# rtc_c register map
Vendor: Texas Instruments
Peripheral module from a debugger description file (folder MSP432).
Registers are 16-bit, read-write, no defined reset value unless marked. A register's access mark holds for its fields unless they carry their own. Offsets are as the file gives them; lines under a group give offsets from that group; [hi:lo] are bit positions; {n}, {i} and the like mark numbered series; 'fields as' and 'values as' point back to an identical list; <NAME> marks a mode.

## RTC_C
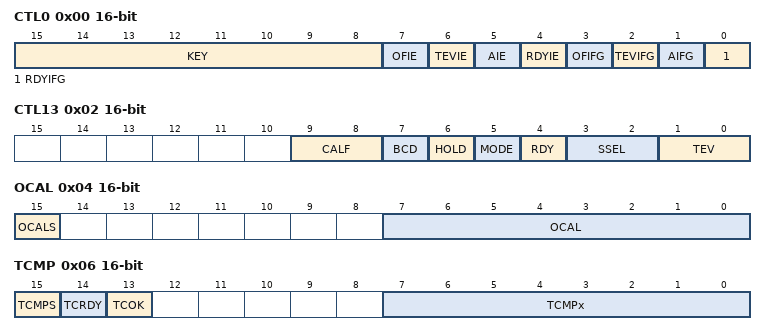
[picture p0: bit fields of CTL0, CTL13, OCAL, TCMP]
0x00 CTL0 — RTCCTL0 Register
  [15:8] KEY — Real-time clock key
  [7] OFIE — 32-kHz crystal oscillator fault interrupt enable
  [6] TEVIE — Real-time clock time event interrupt enable
  [5] AIE — Real-time clock alarm interrupt enable
  [4] RDYIE — Real-time clock ready interrupt enable
  [3] OFIFG — 32-kHz crystal oscillator fault interrupt flag
  [2] TEVIFG — Real-time clock time event interrupt flag
  [1] AIFG — Real-time clock alarm interrupt flag
  [0] RDYIFG — Real-time clock ready interrupt flag
0x02 CTL13 — RTCCTL13 Register
  [9:8] CALF — Real-time clock calibration frequency
    0=CALF__0 (No frequency output to RTCCLK pin); 1=CALF__1 (512 Hz); 2=CALF__2 (256 Hz); 3=CALF__3 (1 Hz)
  [7] BCD — Real-time clock BCD select
    0=BCD__0 (Binary (hexadecimal) code selected); 1=BCD__1 (Binary coded decimal (BCD) code selected)
  [6] HOLD — Real-time clock hold
    0=HOLD__0 (Real-time clock is operational); 1=HOLD__1 (When set, the calendar is stopped as well as the prescale count)
  [5] MODE
    1=MODE__1 (Calendar mode. Always reads a value of 1.)
  [4] RDY — Real-time clock ready
    0=RDY__0 (RTC time values in transition); 1=RDY__1 (RTC time values safe for reading)
  [3:2] SSEL — Real-time clock source select.
    0=SSEL__0 (BCLK)
  [1:0] TEV — Real-time clock time event
    0=TEV__0 (Minute changed); 1=TEV__1 (Hour changed); 2=TEV__2 (Every day at midnight (00:00)); 3=TEV__3 (Every day at noon (12:00))
0x04 OCAL — RTCOCAL Register
  [15] OCALS — Real-time clock offset error calibration sign
    0=OCALS__0 (Down calibration. Frequency adjusted down.); 1=OCALS__1 (Up calibration. Frequency adjusted up.)
  [7:0] OCAL — Real-time clock offset error calibration
0x06 TCMP — RTCTCMP Register
  [15] TCMPS — Real-time clock temperature compensation sign
    0=TCMPS__0 (Down calibration. Frequency adjusted down); 1=TCMPS__1 (Up calibration. Frequency adjusted up)
  [14] TCRDY — Real-time clock temperature compensation ready
  [13] TCOK — Real-time clock temperature compensation write OK
    0=TCOK__0 (Write to RTCTCMPx is unsuccessful); 1=TCOK__1 (Write to RTCTCMPx is successful)
  [7:0] TCMPx — Real-time clock temperature compensation
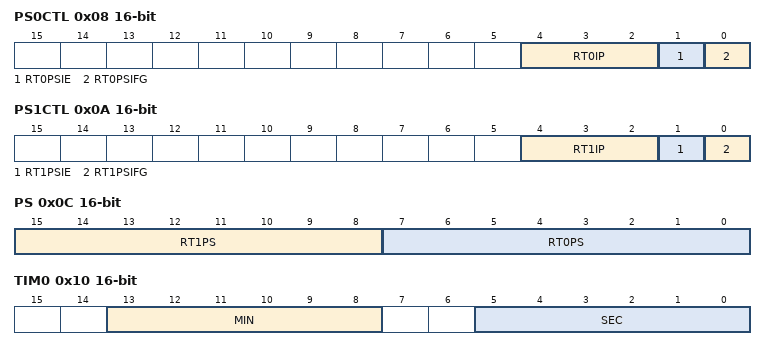
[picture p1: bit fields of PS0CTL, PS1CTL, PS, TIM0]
0x08 PS0CTL — Real-Time Clock Prescale Timer 0 Control Register
  [4:2] RT0IP — Prescale timer 0 interrupt interval
    0=RT0IP__0 (Divide by 2); 1=RT0IP__1 (Divide by 4); 2=RT0IP__2 (Divide by 8); 3=RT0IP__3 (Divide by 16); 4=RT0IP__4 (Divide by 32); 5=RT0IP__5 (Divide by 64); 6=RT0IP__6 (Divide by 128); 7=RT0IP__7 (Divide by 256)
  [1] RT0PSIE — Prescale timer 0 interrupt enable
    0=RT0PSIE__0 (Interrupt not enabled); 1=RT0PSIE__1 (Interrupt enabled)
  [0] RT0PSIFG — Prescale timer 0 interrupt flag
    0=RT0PSIFG__0 (No time event occurred); 1=RT0PSIFG__1 (Time event occurred)
0x0A PS1CTL — Real-Time Clock Prescale Timer 1 Control Register
  [4:2] RT1IP — Prescale timer 1 interrupt interval
    0=RT1IP__0 (Divide by 2); 1=RT1IP__1 (Divide by 4); 2=RT1IP__2 (Divide by 8); 3=RT1IP__3 (Divide by 16); 4=RT1IP__4 (Divide by 32); 5=RT1IP__5 (Divide by 64); 6=RT1IP__6 (Divide by 128); 7=RT1IP__7 (Divide by 256)
  [1] RT1PSIE — Prescale timer 1 interrupt enable
    0=RT1PSIE__0 (Interrupt not enabled); 1=RT1PSIE__1 (Interrupt enabled (LPM3/LPM3.5 wake-up enabled))
  [0] RT1PSIFG — Prescale timer 1 interrupt flag
    0=RT1PSIFG__0 (No time event occurred); 1=RT1PSIFG__1 (Time event occurred)
0x0C PS — Real-Time Clock Prescale Timer Counter Register
  [15:8] RT1PS — Prescale timer 1 counter value
  [7:0] RT0PS — Prescale timer 0 counter value
0x0E IV — Real-Time Clock Interrupt Vector Register
  [15:0] IV — Real-time clock interrupt vector value
    0=IV__0 (No interrupt pending); 2=IV__2 (Interrupt Source: RTC oscillator failure; Interrupt Flag: RTCOF); 4=IV__4 (Interrupt Source: RTC ready; Interrupt Flag: RTCRDYIFG); 6=IV__6 (Interrupt Source: RTC interval timer; Interrupt Flag: RTCTEVIFG); 8=IV__8 (Interrupt Source: RTC user alarm; Interrupt Flag: RTCAIFG); 10=IV__16 (Interrupt Source: RTC prescaler 0; Interrupt Flag: RT0PSIFG); 12=IV__18 (Interrupt Source: RTC prescaler 1; Interrupt Flag: RT1PSIFG)
0x10 TIM0 — RTCTIM0 Register – Hexadecimal Format
  [13:8] MIN — Minutes (0 to 59)
  [5:0] SEC — Seconds (0 to 59)
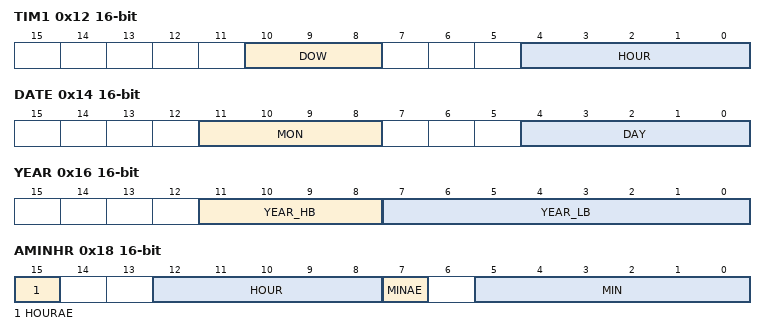
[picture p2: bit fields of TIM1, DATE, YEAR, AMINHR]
0x12 TIM1 — Real-Time Clock Hour, Day of Week
  [10:8] DOW — Day of week (0 to 6)
  [4:0] HOUR — Hours (0 to 23)
0x14 DATE — RTCDATE - Hexadecimal Format
  [11:8] MON — Month (1 to 12)
  [4:0] DAY — Day of month (1 to 28, 29, 30, 31)
0x16 YEAR — RTCYEAR Register – Hexadecimal Format
  [11:8] YEAR_HB — Year – high byte. Valid values for Year are 0 to 4095.
  [7:0] YEAR_LB — Year – low byte. Valid values for Year are 0 to 4095.
0x18 AMINHR — RTCMINHR - Hexadecimal Format
  [15] HOURAE — Alarm enable
  [12:8] HOUR — Hours (0 to 23)
  [7] MINAE — Alarm enable
  [5:0] MIN — Minutes (0 to 59)
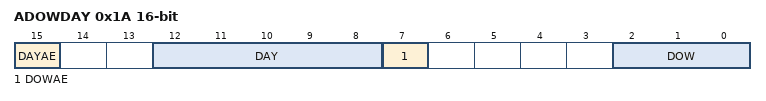
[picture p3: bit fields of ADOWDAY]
0x1A ADOWDAY — RTCADOWDAY - Hexadecimal Format
  [15] DAYAE — Alarm enable
  [12:8] DAY — Day of month (1 to 28, 29, 30, 31)
  [7] DOWAE — Alarm enable
  [2:0] DOW — Day of week (0 to 6)
0x1C BIN2BCD — Binary-to-BCD Conversion Register
  [15:0] BIN2BCD — Read: 16-bit BCD conversion of previously written 12-bit binary
0x1E BCD2BIN — BCD-to-Binary Conversion Register
  [15:0] BCD2BIN — Read: 12-bit binary conversion of previously written 16-bit BCD
